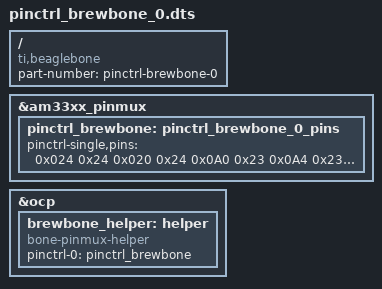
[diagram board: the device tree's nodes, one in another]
/*
 * Copyright (C) 2012 Texas Instruments Incorporated - http://www.ti.com/
 *
 * This program is free software; you can redistribute it and/or modify
 * it under the terms of the GNU General Public License version 2 as
 * published by the Free Software Foundation.
 *
 * https://github.com/jadonk/validation-scripts/tree/master/test-capemgr
 *
 */

/dts-v1/;
/plugin/;

/ {
    compatible = "ti,beaglebone", "ti,beaglebone-black";

    /* identification */
    part-number = "pinctrl-brewbone-0";

    fragment@0 {
        target = <&am33xx_pinmux>;
        __overlay__ {
            pinctrl_brewbone: pinctrl_brewbone_0_pins {
                pinctrl-single,pins = <
                    0x024 0x24 /* P8_13 OUTPUT | MODE7 */
					0x020 0x24 /* P8_19 OUTPUT | MODE7 */
					0x0A0 0x23 /* P8_45 OUTPUT | MODE7 */
					0x0A4 0x23 /* P8_46 OUTPUT | MODE7 */
					0x154 0x23 /* P9_21 OUTPUT | MODE7 */
					0x150 0x23 /* P9_22 OUTPUT | MODE7 */
					0x194 0x21 /* P9_29 OUTPUT | MODE7 */
					0x190 0x21 /* P9_31 OUTPUT | MODE7 */
                >;
            };
        };
    };

    fragment@1 {
        target = <&ocp>;
        __overlay__ {
            brewbone_helper: helper {
                compatible = "bone-pinmux-helper";
                pinctrl-names = "default";
                pinctrl-0 = <&pinctrl_brewbone>;
                status = "okay";
            };
        };
    };
};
